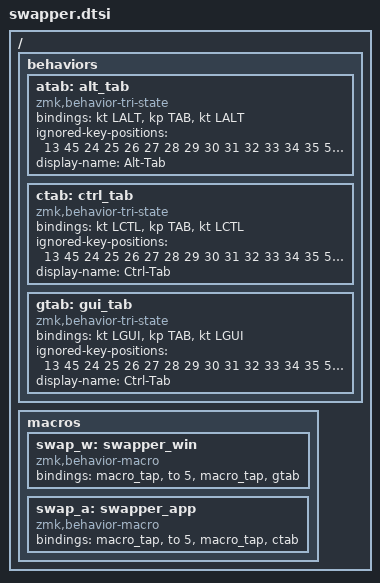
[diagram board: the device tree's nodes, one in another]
#include <behaviors.dtsi>

/ {
    behaviors {
        atab: alt_tab {
            compatible = "zmk,behavior-tri-state";
            #binding-cells = <0>;
            bindings = <&kt LALT>, <&kp TAB>, <&kt LALT>;
            ignored-key-positions = <13 45 24 25 26 27 28 29 30 31 32 33 34 35 50 51 52 53 54 55 56 57>;
            display-name = "Alt-Tab";
        };

        ctab: ctrl_tab {
            compatible = "zmk,behavior-tri-state";
            #binding-cells = <0>;
            bindings = <&kt LCTL>, <&kp TAB>, <&kt LCTL>;
            ignored-key-positions = <13 45 24 25 26 27 28 29 30 31 32 33 34 35 50 51 52 53 54 55 56 57>;
            display-name = "Ctrl-Tab";
        };

        gtab: gui_tab {
            compatible = "zmk,behavior-tri-state";
            #binding-cells = <0>;
            bindings = <&kt LGUI>, <&kp TAB>, <&kt LGUI>;
            ignored-key-positions = <13 45 24 25 26 27 28 29 30 31 32 33 34 35 50 51 52 53 54 55 56 57>;
            display-name = "Ctrl-Tab";
        };
    };

    macros {
        /**
         * Swap windows
         * Windows/Linux: Grave-Tab
         * MacOS: Ctrl-Tab (Cmd-Tab if CMD_SWAP)
         */
        swap_w: swapper_win {
            compatible = "zmk,behavior-macro";
            #binding-cells = <0>;
            bindings
                = <&macro_tap &to 5>
                , <&macro_tap &gtab>
                ;
        };

        /**
         * Swap applications
         * Windows/Linux: Alt-Tab
         * MacOS: Cmd-Tab
         */
        swap_a: swapper_app {
            compatible = "zmk,behavior-macro";
            #binding-cells = <0>;
            bindings
                = <&macro_tap &to 5>
                , <&macro_tap &ctab>
                ;
        };
    };
};
